AUTOSAR XML (schema 314)
package /ComponentType
  internal behavior Sa_BkCpPc_InternalBehavior: component=Sa_BkCpPc
    timing event TMT_BkCpPc_Per1: mode-dependency=dependent-on-mode=[SystemState.Mode.DISABLE, SystemState.Mode.OFF], start-on-event=BkCpPc_Per1, period=0.002
    mode switch event MST_BkCpPc_Trns1_0: start-on-event=BkCpPc_Trns1, activation=ENTRY, mode=SystemState.Mode.DISABLE
    mode switch event MST_BkCpPc_Trns2_0: start-on-event=BkCpPc_Trns2, activation=ENTRY, mode=SystemState.Mode.WARMINIT
    operation invoked event OIT_CapPcDcStub_OP_SET_CapPcDcStub_OP_SET: start-on-event=CapPcDcStub_OP_SET, operation=CapPcDcStub.OP_SET
    port-api-options:
      enable-take-address=false, indirect-api=false, port=Batt
      enable-take-address=false, indirect-api=false, port=BattSwitched
      enable-take-address=false, indirect-api=false, port=CapPcDcStub
      enable-take-address=false, indirect-api=false, port=MotorVelocityMRFUnfiltered
      enable-take-address=false, indirect-api=false, port=NxtrDiagMgr
      enable-take-address=false, indirect-api=false, port=OVERRIDESIGDIAGADC
      enable-take-address=false, indirect-api=false, port=PhyCapDischarge
      enable-take-address=false, indirect-api=false, port=PhyCapPrecharge
      enable-take-address=false, indirect-api=false, port=PMOSDIAGADC
      enable-take-address=false, indirect-api=false, port=PwrDiscATestComplete
      enable-take-address=false, indirect-api=false, port=PwrDiscATestStart
      enable-take-address=false, indirect-api=false, port=PwrDiscBTestComplete
      enable-take-address=false, indirect-api=false, port=PwrDiscBTestStart
      enable-take-address=false, indirect-api=false, port=PwrDiscClosed
      enable-take-address=false, indirect-api=false, port=SystemState
      enable-take-address=false, indirect-api=false, port=SystemTime
    4 x runnable:
      BkCpPc_Per1
        7 x data read access:
          READ_Batt_Volt_f32: data-element=Batt.Volt_f32
          READ_BattSwitched_Volt_f32: data-element=BattSwitched.Volt_f32
          READ_MotorVelocityMRFUnfiltered_MtrRadpS_f32: data-element=MotorVelocityMRFUnfiltered.MtrRadpS_f32
          READ_OVERRIDESIGDIAGADC_Volt_f32: data-element=OVERRIDESIGDIAGADC.Volt_f32
          READ_PMOSDIAGADC_Volt_f32: data-element=PMOSDIAGADC.Volt_f32
          READ_PwrDiscATestStart_Cnt_lgc: data-element=PwrDiscATestStart.Cnt_lgc
          READ_PwrDiscBTestStart_Cnt_lgc: data-element=PwrDiscBTestStart.Cnt_lgc
        data write access WRITE_PwrDiscATestComplete_Cnt_lgc: data-element=PwrDiscATestComplete.Cnt_lgc
        data write access WRITE_PwrDiscBTestComplete_Cnt_lgc: data-element=PwrDiscBTestComplete.Cnt_lgc
        data write access WRITE_PwrDiscClosed_Cnt_lgc: data-element=PwrDiscClosed.Cnt_lgc
        5 x sync call, all with timeout=0:
          SC_NxtrDiagMgr_SetNTCStatus: operation=NxtrDiagMgr.SetNTCStatus
          SC_PhyCapDischarge_OP_SET: operation=PhyCapDischarge.OP_SET
          SC_PhyCapPrecharge_OP_SET: operation=PhyCapPrecharge.OP_SET
          SC_SystemTime_DtrmnElapsedTime_mS_u16: operation=SystemTime.DtrmnElapsedTime_mS_u16
          SC_SystemTime_GetSystemTime_mS_u32: operation=SystemTime.GetSystemTime_mS_u32
      BkCpPc_Trns1
        data write access WRITE_PwrDiscATestComplete_Cnt_lgc: data-element=PwrDiscATestComplete.Cnt_lgc
        data write access WRITE_PwrDiscBTestComplete_Cnt_lgc: data-element=PwrDiscBTestComplete.Cnt_lgc
        sync call SC_NxtrDiagMgr_SetNTCStatus: operation=NxtrDiagMgr.SetNTCStatus, timeout=0
        sync call SC_PhyCapDischarge_OP_SET: operation=PhyCapDischarge.OP_SET, timeout=0
        sync call SC_PhyCapPrecharge_OP_SET: operation=PhyCapPrecharge.OP_SET, timeout=0
      BkCpPc_Trns2
        data write access WRITE_PwrDiscATestComplete_Cnt_lgc: data-element=PwrDiscATestComplete.Cnt_lgc
        data write access WRITE_PwrDiscBTestComplete_Cnt_lgc: data-element=PwrDiscBTestComplete.Cnt_lgc
        data write access WRITE_PwrDiscClosed_Cnt_lgc: data-element=PwrDiscClosed.Cnt_lgc
        sync call SC_PhyCapDischarge_OP_SET: operation=PhyCapDischarge.OP_SET, timeout=0
        sync call SC_PhyCapPrecharge_OP_SET: operation=PhyCapPrecharge.OP_SET, timeout=0
      CapPcDcStub_OP_SET: can-be-invoked-concurrently=true
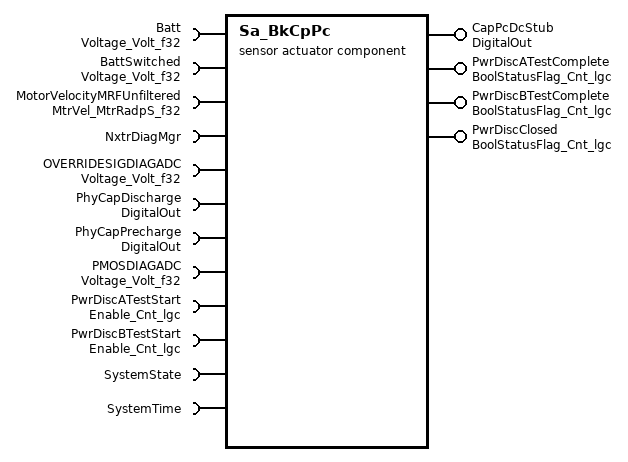
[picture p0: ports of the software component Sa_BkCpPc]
  sensor actuator software component type Sa_BkCpPc
    4 x provide port:
      CapPcDcStub: server-com-spec{operation=OP_SET, queue-length=1}, provided-interface=DigitalOut
      PwrDiscATestComplete: unqueued-sender-com-spec{data-element=Cnt_lgc, can-invalidate=false, init-value=D_FALSE_CNT_LGC}, provided-interface=BoolStatusFlag_Cnt_lgc
      PwrDiscBTestComplete: unqueued-sender-com-spec{data-element=Cnt_lgc, can-invalidate=false, init-value=D_FALSE_CNT_LGC}, provided-interface=BoolStatusFlag_Cnt_lgc
      PwrDiscClosed: unqueued-sender-com-spec{data-element=Cnt_lgc, can-invalidate=false, init-value=D_FALSE_CNT_LGC}, provided-interface=BoolStatusFlag_Cnt_lgc
    12 x require port:
      Batt: unqueued-receiver-com-spec{data-element=Volt_f32, init-value=D_ZERO_ULS_F32}, required-interface=Voltage_Volt_f32
      BattSwitched: unqueued-receiver-com-spec{data-element=Volt_f32, init-value=D_ZERO_ULS_F32}, required-interface=Voltage_Volt_f32
      MotorVelocityMRFUnfiltered: unqueued-receiver-com-spec{data-element=MtrRadpS_f32, init-value=D_ZERO_ULS_F32}, required-interface=MtrVel_MtrRadpS_f32
      NxtrDiagMgr: required-com-specs=[GetNTCActive, GetNTCFailed, GetNTCStatus, SetNTCStatus], required-interface=NxtrDiagMgr
      OVERRIDESIGDIAGADC: unqueued-receiver-com-spec{data-element=Volt_f32, init-value=D_ZERO_ULS_F32}, required-interface=Voltage_Volt_f32
      PhyCapDischarge: client-com-spec=OP_SET, required-interface=DigitalOut
      PhyCapPrecharge: client-com-spec=OP_SET, required-interface=DigitalOut
      PMOSDIAGADC: unqueued-receiver-com-spec{data-element=Volt_f32, init-value=D_ZERO_ULS_F32}, required-interface=Voltage_Volt_f32
      PwrDiscATestStart: unqueued-receiver-com-spec{data-element=Cnt_lgc, init-value=D_FALSE_CNT_LGC}, required-interface=Enable_Cnt_lgc
      PwrDiscBTestStart: unqueued-receiver-com-spec{data-element=Cnt_lgc, init-value=D_FALSE_CNT_LGC}, required-interface=Enable_Cnt_lgc
      SystemState: required-interface=SystemState
      SystemTime: required-interface=SystemTime
        required-com-specs:
          DtrmnElapsedTime_mS_u16
          DtrmnElapsedTime_mS_u32
          DtrmnElapsedTime_uS_u16
          DtrmnElapsedTime_uS_u32
          GetSystemTime_mS_u32
          GetSystemTime_uS_u32
  swc implementation Sa_BkCpPc_Implementation: behavior=Sa_BkCpPc_InternalBehavior
    code-descriptors:
      code Code: type=SRC
